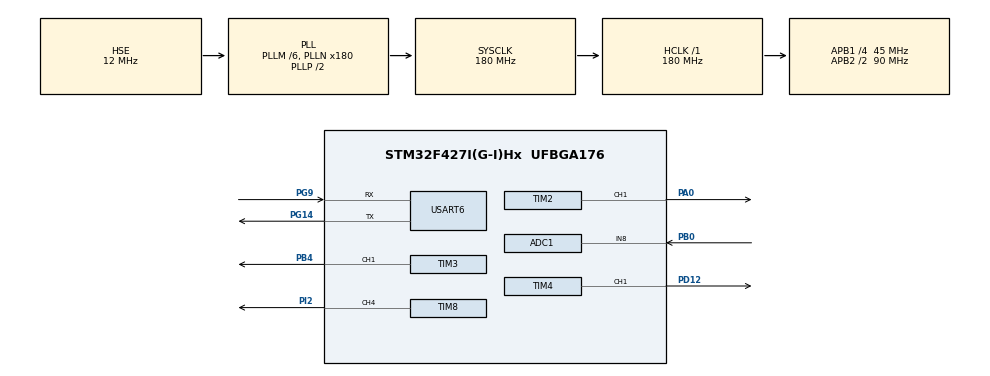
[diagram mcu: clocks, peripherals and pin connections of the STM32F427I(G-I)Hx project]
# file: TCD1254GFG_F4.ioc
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ADC1.Channel-0\#ChannelRegularConversion=ADC_CHANNEL_8
ADC1.ContinuousConvMode=DISABLE
ADC1.ExternalTrigConv=ADC_EXTERNALTRIGCONV_T3_TRGO
ADC1.InjNumberOfConversion=0
ADC1.NbrOfConversionFlag=1
ADC1.Rank-0\#ChannelRegularConversion=1
ADC1.Resolution=ADC_RESOLUTION_6B
ADC1.SamplingTime-0\#ChannelRegularConversion=ADC_SAMPLETIME_3CYCLES
ADC1.ScanConvMode=DISABLE
ADC1.master=1
Dma.ADC1.0.Direction=DMA_PERIPH_TO_MEMORY
Dma.ADC1.0.FIFOMode=DMA_FIFOMODE_DISABLE
Dma.ADC1.0.Instance=DMA2_Stream0
Dma.ADC1.0.MemDataAlignment=DMA_MDATAALIGN_HALFWORD
Dma.ADC1.0.MemInc=DMA_MINC_ENABLE
Dma.ADC1.0.Mode=DMA_NORMAL
Dma.ADC1.0.PeriphDataAlignment=DMA_PDATAALIGN_HALFWORD
Dma.ADC1.0.PeriphInc=DMA_PINC_DISABLE
Dma.ADC1.0.Priority=DMA_PRIORITY_VERY_HIGH
Dma.Request0=ADC1
Dma.Request1=USART6_TX
Dma.USART6_TX.1.Direction=DMA_MEMORY_TO_PERIPH
Dma.USART6_TX.1.FIFOMode=DMA_FIFOMODE_DISABLE
Dma.USART6_TX.1.Instance=DMA2_Stream6
Dma.USART6_TX.1.MemDataAlignment=DMA_MDATAALIGN_BYTE
Dma.USART6_TX.1.MemInc=DMA_MINC_ENABLE
Dma.USART6_TX.1.Mode=DMA_NORMAL
Dma.USART6_TX.1.PeriphDataAlignment=DMA_PDATAALIGN_BYTE
Dma.USART6_TX.1.PeriphInc=DMA_PINC_DISABLE
Dma.USART6_TX.1.Priority=DMA_PRIORITY_LOW
Mcu.Family=STM32F4
Mcu.Name=STM32F427I(G-I)Hx
Mcu.Package=UFBGA176
NVIC.ADC_IRQn=true\:0\:0\:false\:false\:true\:true\:true\:true
NVIC.DMA2_Stream0_IRQn=true\:0\:0\:false\:false\:true\:false\:true\:true
NVIC.DMA2_Stream6_IRQn=true\:0\:0\:false\:false\:true\:false\:true\:true
NVIC.PriorityGroup=NVIC_PRIORITYGROUP_4
NVIC.TIM3_IRQn=true\:0\:0\:false\:false\:true\:true\:true\:true
NVIC.USART6_IRQn=true\:0\:0\:false\:false\:true\:true\:true\:true
PA0/WKUP.GPIO_Speed=GPIO_SPEED_FREQ_VERY_HIGH
PA0/WKUP.Signal=S_TIM2_CH1_ETR
PB0.Signal=ADCx_IN8
PB4.Signal=S_TIM3_CH1
PD12.GPIO_Speed=GPIO_SPEED_FREQ_VERY_HIGH
PD12.Signal=S_TIM4_CH1
PG14.Mode=Asynchronous
PG14.Signal=USART6_TX
PG9.Mode=Asynchronous
PG9.Signal=USART6_RX
PH0/OSC_IN.Mode=HSE-External-Oscillator
PH0/OSC_IN.Signal=RCC_OSC_IN
PH1/OSC_OUT.Mode=HSE-External-Oscillator
PH1/OSC_OUT.Signal=RCC_OSC_OUT
PI0.GPIO_Speed=GPIO_SPEED_FREQ_VERY_HIGH
PI0.Signal=S_TIM5_CH4
PI2.GPIO_Speed=GPIO_SPEED_FREQ_VERY_HIGH
PI2.Signal=S_TIM8_CH4
ProjectManager.HeapSize=0x200
ProjectManager.StackSize=0x400
ProjectManager.TargetToolchain=Makefile
RCC.48MHZClocksFreq_Value=90000000
RCC.AHBFreq_Value=180000000
RCC.APB1CLKDivider=RCC_HCLK_DIV4
RCC.APB1Freq_Value=45000000
RCC.APB1TimFreq_Value=90000000
RCC.APB2CLKDivider=RCC_HCLK_DIV2
RCC.APB2Freq_Value=90000000
RCC.APB2TimFreq_Value=180000000
RCC.CortexFreq_Value=180000000
RCC.HCLKFreq_Value=180000000
RCC.HSE_VALUE=12000000
RCC.HSI_VALUE=16000000
RCC.LSE_VALUE=32768
RCC.PLLM=6
RCC.PLLN=180
RCC.PLLSourceVirtual=RCC_PLLSOURCE_HSE
RCC.SYSCLKFreq_VALUE=180000000
RCC.SYSCLKSource=RCC_SYSCLKSOURCE_PLLCLK
RCC.VCOOutputFreq_Value=360000000
SH.ADCx_IN8.0=ADC1_IN8,IN8
SH.S_TIM2_CH1_ETR.0=TIM2_CH1,PWM Generation1 CH1
SH.S_TIM3_CH1.0=TIM3_CH1,PWM Generation1 CH1
SH.S_TIM4_CH1.0=TIM4_CH1,PWM Generation1 CH1
SH.S_TIM5_CH4.0=TIM5_CH4
SH.S_TIM8_CH4.0=TIM8_CH4,PWM Generation4 CH4
STMicroelectronics.X-CUBE-ALGOBUILD.1.3.0.LibraryCcDSPOoLibraryJjDSPOoLibrary=true
TIM2.AutoReloadPreload=TIM_AUTORELOAD_PRELOAD_ENABLE
TIM2.Channel-PWM\ Generation1\ CH1=TIM_CHANNEL_1
TIM2.OCFastMode_PWM-PWM\ Generation1\ CH1=TIM_OCFAST_ENABLE
TIM2.OCMode_PWM-PWM\ Generation1\ CH1=TIM_OCMODE_PWM2
TIM2.OCPolarity_1=TIM_OCPOLARITY_LOW
TIM2.Period=10+5+1-2
TIM2.Prescaler=9-1
TIM2.Pulse-PWM\ Generation1\ CH1=5
TIM2.TIM_MasterSlaveMode=TIM_MASTERSLAVEMODE_DISABLE
TIM3.AutoReloadPreload=TIM_AUTORELOAD_PRELOAD_ENABLE
TIM3.Channel-PWM\ Generation1\ CH1=TIM_CHANNEL_1
TIM3.Period=5-1
TIM3.Prescaler=9-1
TIM3.Pulse-PWM\ Generation1\ CH1=2
TIM3.TIM_MasterOutputTrigger=TIM_TRGO_UPDATE
TIM4.AutoReloadPreload=TIM_AUTORELOAD_PRELOAD_ENABLE
TIM4.Channel-PWM\ Generation1\ CH1=TIM_CHANNEL_1
TIM4.OCFastMode_PWM-PWM\ Generation1\ CH1=TIM_OCFAST_ENABLE
TIM4.OCMode_PWM-PWM\ Generation1\ CH1=TIM_OCMODE_PWM2
TIM4.OCPolarity_1=TIM_OCPOLARITY_HIGH
TIM4.Period=60+1-1
TIM4.Prescaler=9-1
TIM4.Pulse-PWM\ Generation1\ CH1=1
TIM8.AutoReloadPreload=TIM_AUTORELOAD_PRELOAD_ENABLE
TIM8.Channel-PWM\ Generation4\ CH4=TIM_CHANNEL_4
TIM8.OCFastMode_PWM-PWM\ Generation4\ CH4=TIM_OCFAST_ENABLE
TIM8.OCMode_PWM-PWM\ Generation4\ CH4=TIM_OCMODE_PWM2
TIM8.Period=5-1
TIM8.Prescaler=9-1
TIM8.Pulse-PWM\ Generation4\ CH4=2
TIM8.TIM_MasterOutputTrigger=TIM_TRGO_UPDATE
USART6.VirtualMode=VM_ASYNC
VP_ADC1_Vref_Input.Mode=IN-Vrefint
VP_STMicroelectronics.X-CUBE-ALGOBUILD_VS_DSPOoLibraryJjLibrary_1.3.0_1.3.0.Mode=DSPOoLibraryJjLibrary
VP_TIM2_VS_OPM.Mode=OPM_bit
VP_TIM4_VS_OPM.Mode=OPM_bit
board=custom

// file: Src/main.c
/* USER CODE BEGIN Header */
/**
 ******************************************************************************
 * @file           : main.c
 * @brief          : Main program body
 ******************************************************************************
 * @attention
 *
 * Copyright (c) 2023 STMicroelectronics.
 * All rights reserved.
 *
 * This software is licensed under terms that can be found in the LICENSE file
 * in the root directory of this software component.
 * If no LICENSE file comes with this software, it is provided AS-IS.
 *
 ******************************************************************************
 */
/* USER CODE END Header */
#include "main.h"
#include "adc.h"
#include "dma.h"
#include "tim.h"
#include "usart.h"
#include "gpio.h"

/* USER CODE BEGIN Includes */
#include "tcddriver.h"
/* USER CODE END Includes */

void SystemClock_Config(void);

int main(void)
{

    /* MCU Configuration--------------------------------------------------------*/

    /* Reset of all peripherals, Initializes the Flash interface and the Systick. */
    HAL_Init();

    /* Configure the system clock */
    SystemClock_Config();

    /* Initialize all configured peripherals */
    MX_GPIO_Init();
    MX_DMA_Init();
    MX_ADC1_Init();
    MX_TIM8_Init();
    MX_TIM4_Init();
    MX_TIM3_Init();
    MX_TIM2_Init();
    MX_USART6_UART_Init();
    /* USER CODE BEGIN 2 */
    tcdinit(&hdma_adc1, &iirfilter, &kf);
    /* USER CODE END 2 */

    /* Infinite loop */
    /* USER CODE BEGIN WHILE */
    while (1) {

        scanstart(&cds);
        // uint8_t Senbuff[] = "\r\n**** Serial Output Message by DMA ***\r\n   UART DMA Test \r\n";
        // HAL_UART_Transmit_DMA(&huart6, (uint8_t *)Senbuff, sizeof(Senbuff));
        // HAL_Delay(1000);
        // uint16_t data[12] = {0x0102, 0x0201, 0x0201, 0x0201, 0x0201, 0x0201, 0x0201, 0x0201, 0x0201, 0x0201, 0x0201, 0x0102};
        // trans_ccd_data(data, 12);
        /* USER CODE END WHILE */

        /* USER CODE BEGIN 3 */
        scanstop(&cds, &iirfilter);
    }
    /* USER CODE END 3 */
}

void SystemClock_Config(void)
{
    RCC_OscInitTypeDef RCC_OscInitStruct = {0};
    RCC_ClkInitTypeDef RCC_ClkInitStruct = {0};

    /** Configure the main internal regulator output voltage
     */
    __HAL_RCC_PWR_CLK_ENABLE();
    __HAL_PWR_VOLTAGESCALING_CONFIG(PWR_REGULATOR_VOLTAGE_SCALE1);

    /** Initializes the RCC Oscillators according to the specified parameters
     * in the RCC_OscInitTypeDef structure.
     */
    RCC_OscInitStruct.OscillatorType = RCC_OSCILLATORTYPE_HSE;
    RCC_OscInitStruct.HSEState       = RCC_HSE_ON;
    RCC_OscInitStruct.PLL.PLLState   = RCC_PLL_ON;
    RCC_OscInitStruct.PLL.PLLSource  = RCC_PLLSOURCE_HSE;
    RCC_OscInitStruct.PLL.PLLM       = 6;
    RCC_OscInitStruct.PLL.PLLN       = 180;
    RCC_OscInitStruct.PLL.PLLP       = RCC_PLLP_DIV2;
    RCC_OscInitStruct.PLL.PLLQ       = 4;
    if (HAL_RCC_OscConfig(&RCC_OscInitStruct) != HAL_OK) {
        Error_Handler();
    }

    /** Activate the Over-Drive mode
     */
    if (HAL_PWREx_EnableOverDrive() != HAL_OK) {
        Error_Handler();
    }

    /** Initializes the CPU, AHB and APB buses clocks
     */
    RCC_ClkInitStruct.ClockType      = RCC_CLOCKTYPE_HCLK | RCC_CLOCKTYPE_SYSCLK | RCC_CLOCKTYPE_PCLK1 | RCC_CLOCKTYPE_PCLK2;
    RCC_ClkInitStruct.SYSCLKSource   = RCC_SYSCLKSOURCE_PLLCLK;
    RCC_ClkInitStruct.AHBCLKDivider  = RCC_SYSCLK_DIV1;
    RCC_ClkInitStruct.APB1CLKDivider = RCC_HCLK_DIV4;
    RCC_ClkInitStruct.APB2CLKDivider = RCC_HCLK_DIV2;

    if (HAL_RCC_ClockConfig(&RCC_ClkInitStruct, FLASH_LATENCY_5) != HAL_OK) {
        Error_Handler();
    }
}

void Error_Handler(void)
{
    __disable_irq();
    while (1) {
    }
}
